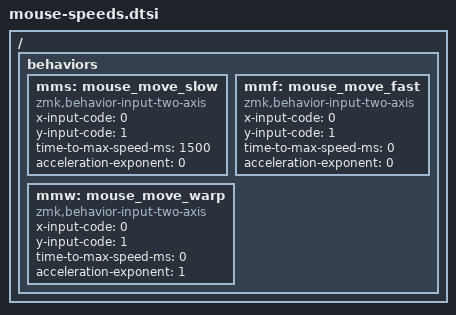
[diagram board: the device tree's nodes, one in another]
// mouse-speeds.dtsi
/ {
    behaviors {
        // Slow mouse - high time to max, minimal acceleration
        mms: mouse_move_slow {
            compatible = "zmk,behavior-input-two-axis";
            #binding-cells = <1>;
            x-input-code = <0>;
            y-input-code = <1>;
            time-to-max-speed-ms = <1500>;
            acceleration-exponent = <0>;
        };
        
        // Fast mouse - instant speed, no acceleration  
        mmf: mouse_move_fast {
            compatible = "zmk,behavior-input-two-axis";
            #binding-cells = <1>;
            x-input-code = <0>;
            y-input-code = <1>;
            time-to-max-speed-ms = <0>;
            acceleration-exponent = <0>;
        };
        
        // Warp mouse - instant max speed
        mmw: mouse_move_warp {
            compatible = "zmk,behavior-input-two-axis";
            #binding-cells = <1>;
            x-input-code = <0>;
            y-input-code = <1>;
            time-to-max-speed-ms = <0>;
            acceleration-exponent = <1>;
        };
    };
};
